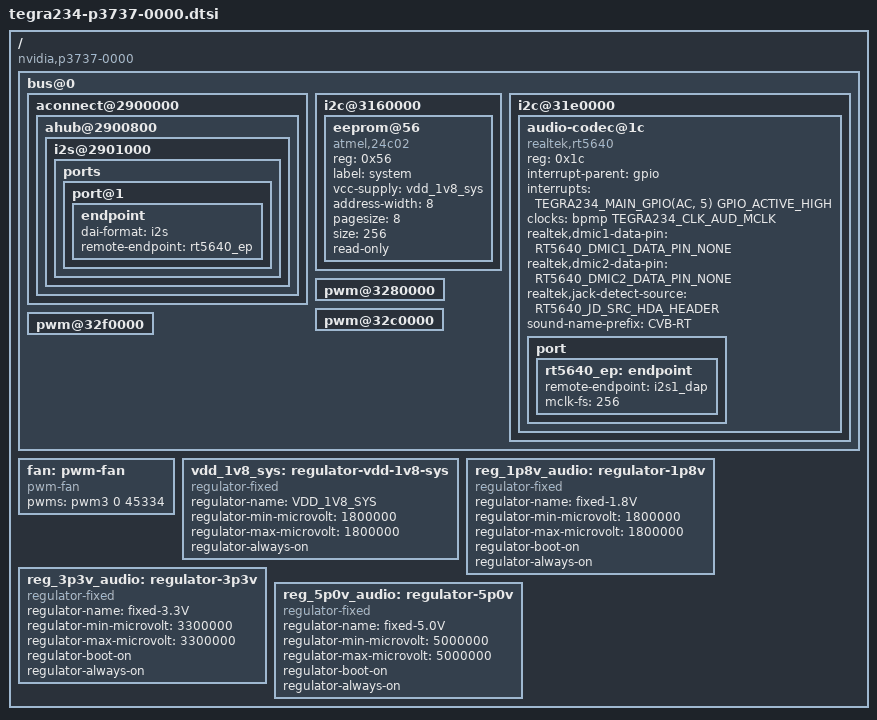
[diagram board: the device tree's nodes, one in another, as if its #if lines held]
// SPDX-License-Identifier: GPL-2.0

#include <dt-bindings/sound/rt5640.h>
//#define USE_RT5640
/ {
	compatible = "nvidia,p3737-0000";

	bus@0 {
		aconnect@2900000 {
			ahub@2900800 {
				i2s@2901000 {
					ports {
						port@1 {
							endpoint {
								dai-format = "i2s";
							#ifdef USE_RT5640
								remote-endpoint = <&rt5640_ep>;
							#else
								remote-endpoint = <&da7212_endpoint>;
							#endif
							};
						};
					};
				};
			};
		};

		i2c@3160000 {
			status = "okay";

			eeprom@56 {
				compatible = "atmel,24c02";
				reg = <0x56>;

				label = "system";
				vcc-supply = <&vdd_1v8_sys>;
				address-width = <8>;
				pagesize = <8>;
				size = <256>;
				read-only;
			};
		};

		i2c@31e0000 {
			status = "okay";
#ifdef USE_RT5640
			audio-codec@1c {
				compatible = "realtek,rt5640";
				reg = <0x1c>;
				interrupt-parent = <&gpio>;
				interrupts = <TEGRA234_MAIN_GPIO(AC, 5) GPIO_ACTIVE_HIGH>;
				clocks = <&bpmp TEGRA234_CLK_AUD_MCLK>;
				clock-names = "mclk";
				realtek,dmic1-data-pin = <RT5640_DMIC1_DATA_PIN_NONE>;
				realtek,dmic2-data-pin = <RT5640_DMIC2_DATA_PIN_NONE>;
				realtek,jack-detect-source = <RT5640_JD_SRC_HDA_HEADER>;
				sound-name-prefix = "CVB-RT";

				port {
					rt5640_ep: endpoint {
						remote-endpoint = <&i2s1_dap>;
						mclk-fs = <256>;
					};
				};
			};
#else
			da7212: codec@1a {
				compatible = "dlg,da7212";
				status = "okay";

				#sound-dai-cells = <0>;
				#address-cells = <1>;
				#size-cells = <0>;

				reg = <0x1a>;

				clocks = <&bpmp TEGRA234_CLK_AUD_MCLK>;
				clock-names = "mclk";

				dlg,micbias1-lvl = <2500>;
				dlg,micbias2-lvl = <2500>;
				dlg,dmic-data-sel = "lrise_rfall";
				dlg,dmic-samplephase = "between_clkedge";
				dlg,dmic-clkrate = <3000000>;

				VDDA-supply = <&reg_1p8v_audio>;
				VDDSP-supply = <&reg_5p0v_audio>;
				VDDMIC-supply = <&reg_3p3v_audio>;
				VDDIO-supply = <&reg_3p3v_audio>;

				port@0 {
					da7212_endpoint: endpoint {
						remote-endpoint = <&i2s1_dap>;
//						mclk-fs = <256>;
					};
				};
			};
#endif
		};

		pwm@3280000 {
			status = "okay";
		};

		pwm@32c0000 {
			status = "okay";
		};

		pwm@32f0000 {
			status = "okay";
		};
	};

	fan: pwm-fan {
		compatible = "pwm-fan";
		pwms = <&pwm3 0 45334>;
		#cooling-cells = <2>;
	};

	vdd_1v8_sys: regulator-vdd-1v8-sys {
		compatible = "regulator-fixed";
		regulator-name = "VDD_1V8_SYS";
		regulator-min-microvolt = <1800000>;
		regulator-max-microvolt = <1800000>;
		regulator-always-on;
	};
#ifndef USE_RT5640
	reg_1p8v_audio: regulator-1p8v {
			compatible = "regulator-fixed";
			regulator-name = "fixed-1.8V";
			regulator-min-microvolt = <1800000>;
			regulator-max-microvolt = <1800000>;
			regulator-boot-on;
			regulator-always-on;
	};

	reg_3p3v_audio: regulator-3p3v {
			compatible = "regulator-fixed";
			regulator-name = "fixed-3.3V";
			regulator-min-microvolt = <3300000>;
			regulator-max-microvolt = <3300000>;
			regulator-boot-on;
			regulator-always-on;
	};
	
	reg_5p0v_audio: regulator-5p0v {
			compatible = "regulator-fixed";
			regulator-name = "fixed-5.0V";
			regulator-min-microvolt = <5000000>;
			regulator-max-microvolt = <5000000>;
			regulator-boot-on;
			regulator-always-on;
	};
#endif
};
